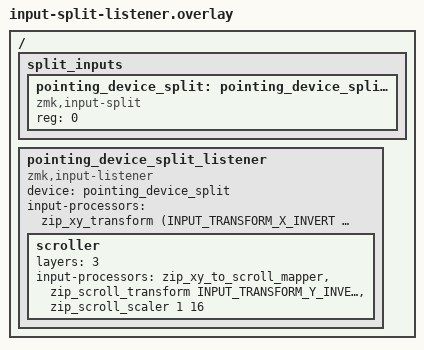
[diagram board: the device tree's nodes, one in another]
/{
    split_inputs {
        #address-cells = <1>;
        #size-cells = <0>;

        pointing_device_split: pointing_device_split@0 {
            compatible = "zmk,input-split";
            reg = <0>;
        };
    };

    pointing_device_split_listener: pointing_device_split_listener {
        compatible = "zmk,input-listener";
        device = <&pointing_device_split>;
        status = "okay";
        input-processors = <&zip_xy_transform (INPUT_TRANSFORM_X_INVERT | INPUT_TRANSFORM_Y_INVERT)>;

        // 以下追加
        scroller {
            layers = <3>;                                      // スクロールレイヤー
            input-processors = <
                &zip_xy_to_scroll_mapper                       // XY移動でスクロール
                &zip_scroll_transform INPUT_TRANSFORM_Y_INVERT // スクロールのY軸を反転
                &zip_scroll_scaler 1 16                        // スクロール感度調整
            >;
        };
     };
};
